# apollo1 register map
Vendor: Ambiq Micro; Series: Apollo; File version: 1.0
CPU: CM4 r1p0, little endian, MPU, FPU, 3 interrupt priority bits
Registers are 32-bit, read-write, reset 0x0 unless marked. A register's access mark holds for its fields unless they carry their own. Offsets are from the block's base; [hi:lo] are bit positions; 'fields as' and 'values as' point back to an identical list.

## IOMSTR0 — I2C/SPI Master
Base 0x50004000
Same registers: IOMSTR1 0x50005000
0x00 FIFO — FIFO Access Port
  [31:0] FIFO — FIFO access port.
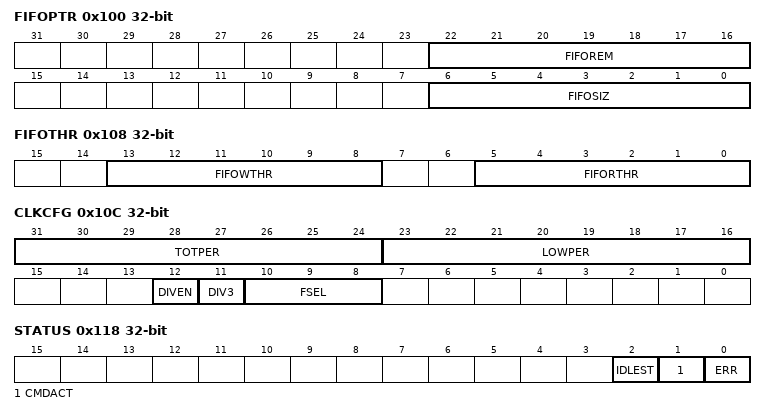
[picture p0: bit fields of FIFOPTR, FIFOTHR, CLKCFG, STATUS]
0x100 FIFOPTR — Current FIFO Pointers
  [22:16] FIFOREM — The number of bytes remaining in the FIFO (i.e. 64-FIFOSIZ).
  [6:0] FIFOSIZ — The number of bytes currently in the FIFO.
0x104 TLNGTH — Transfer Length
  [11:0] TLNGTH — Remaining transfer length.
0x108 FIFOTHR — FIFO Threshold Configuration
  [13:8] FIFOWTHR — FIFO write threshold.
  [5:0] FIFORTHR — FIFO read threshold.
0x10C CLKCFG — I/O Clock Configuration
  [31:24] TOTPER — Clock total count minus 1.
  [23:16] LOWPER — Clock low count minus 1.
  [12] DIVEN — Enable clock division by TOTPER.
    0=DIS (Disable TOTPER division. value.); 1=EN (Enable TOTPER division. value.)
  [11] DIV3 — Enable divide by 3.
    0=DIS (Select divide by 1. value.); 1=EN (Select divide by 3. value.)
  [10:8] FSEL — Select the input clock frequency.
    0=HFRC_DIV64 (Selects the HFRC / 64 as the input clock. value.); 1=HFRC (Selects the HFRC as the input clock. value.); 2=HFRC_DIV2 (Selects the HFRC / 2 as the input clock. value.); 3=HFRC_DIV4 (Selects the HFRC / 4 as the input clock. value.); 4=HFRC_DIV8 (Selects the HFRC / 8 as the input clock. value.); 5=HFRC_DIV16 (Selects the HFRC / 16 as the input clock. value.); 6=HFRC_DIV32 (Selects the HFRC / 32 as the input clock. value.)
0x110 CMD — Command Register
  [31:0] CMD — This register is the I/O Command.
    0=POS_LENGTH (LSB bit position of the CMD LENGTH field. value.); 8=POS_OFFSET (LSB bit position of the CMD OFFSET field. value.); 16=POS_ADDRESS (LSB bit position of the I2C CMD ADDRESS field. value.); 23=POS_UPLNGTH (LSB bit position of the SPI CMD UPLNGTH field. value.); 26=POS_10BIT (LSB bit position of the I2C CMD 10-bit field. value.); 27=POS_LSB (LSB bit position of the CMD LSB-first field. value.); 28=POS_CONT (LSB bit position of the CMD CONTinue field. value.); 29=POS_OPER (LSB bit position of the CMD OPERation field. value.); 255=MSK_LENGTH (LSB bit mask of the CMD LENGTH field. value.); 0xFF00=MSK_OFFSET (LSB bit mask of the CMD OFFSET field. value.); 0xFF0000=MSK_ADDRESS (LSB bit mask of the I2C CMD ADDRESS field. value.); 0x70000=MSK_CHNL (LSB bit mask of the SPI CMD CHANNEL field. value.); 0x7800000=MSK_UPLNGTH (LSB bit mask of the SPI CMD UPLNGTH field. value.); 0x4000000=MSK_10BIT (LSB bit mask of the I2C CMD 10-bit field. value.); 0x8000000=MSK_LSB (LSB bit mask of the CMD LSB-first field. value.); 0x10000000=MSK_CONT (LSB bit mask of the CMD CONTinue field. value.); 0xE0000000=MSK_OPER (LSB bit mask of the CMD OPERation field. value.)
0x114 CMDRPT — Command Repeat Register
  [4:0] CMDRPT — These bits hold the Command repeat count.
0x118 STATUS
  [2] IDLEST — This bit indicates if the I/O state machine is IDLE.
    1=IDLE (The I/O state machine is in the idle state. value.)
  [1] CMDACT — This bit indicates if the I/O Command is active.
    1=ACTIVE (An I/O command is active. value.)
  [0] ERR — This bit indicates if an error interrupt has occurred.
    1=ERROR (An error has been indicated by the IOM. value.)
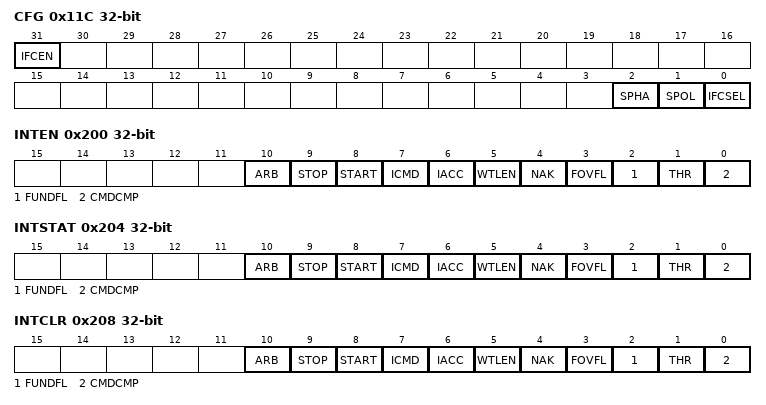
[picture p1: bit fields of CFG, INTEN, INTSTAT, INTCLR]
0x11C CFG — I/O Master Configuration
  [31] IFCEN — This bit enables the IO Master.
    0=DIS (Disable the IO Master. value.); 1=EN (Enable the IO Master. value.)
  [2] SPHA — This bit selects SPI phase.
    0=SAMPLE_LEADING_EDGE (Sample on the leading (first) clock edge. value.); 1=SAMPLE_TRAILING_EDGE (Sample on the trailing (second) clock edge. value.)
  [1] SPOL — This bit selects SPI polarity.
    0=CLK_BASE_0 (The base value of the clock is 0. value.); 1=CLK_BASE_1 (The base value of the clock is 1. value.)
  [0] IFCSEL — This bit selects the I/O interface.
    0=I2C (Selects I2C interface for the I/O Master. value.); 1=SPI (Selects SPI interface for the I/O Master. value.)
0x200 INTEN — IO Master Interrupts: Enable
  [10] ARB — This is the arbitration loss interrupt.
  [9] STOP — This is the STOP command interrupt.
  [8] START — This is the START command interrupt.
  [7] ICMD — This is the illegal command interrupt.
  [6] IACC — This is the illegal FIFO access interrupt.
  [5] WTLEN — This is the write length mismatch interrupt.
  [4] NAK — This is the I2C NAK interrupt.
  [3] FOVFL — This is the Read FIFO Overflow interrupt.
  [2] FUNDFL — This is the Write FIFO Underflow interrupt.
  [1] THR — This is the FIFO Threshold interrupt.
  [0] CMDCMP — This is the Command Complete interrupt.
0x204 INTSTAT — IO Master Interrupts: Status
  fields as INTEN
0x208 INTCLR — IO Master Interrupts: Clear
  fields as INTEN
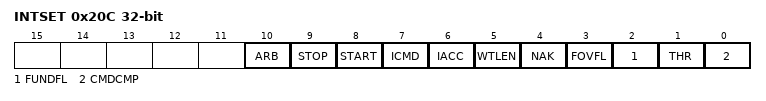
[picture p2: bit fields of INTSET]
0x20C INTSET — IO Master Interrupts: Set
  fields as INTEN

## Notices in the file
Copyright (C) 2012-2014 ARM Limited. All rights reserved.
Purpose: System Viewer Description (SVD) Example (Schema Version 1.1)
This is a description of a none-existent and incomplete device
for demonstration purposes only.
Redistribution and use in source and binary forms, with or without
modification, are permitted provided that the following conditions are met:
- Redistributions of source code must retain the above copyright
notice, this list of conditions and the following disclaimer.
- Redistributions in binary form must reproduce the above copyright
notice, this list of conditions and the following disclaimer in the
documentation and/or other materials provided with the distribution.
- Neither the name of ARM nor the names of its contributors may be used
to endorse or promote products derived from this software without
specific prior written permission.
THIS SOFTWARE IS PROVIDED BY THE COPYRIGHT HOLDERS AND CONTRIBUTORS "AS IS"
AND ANY EXPRESS OR IMPLIED WARRANTIES, INCLUDING, BUT NOT LIMITED TO, THE
IMPLIED WARRANTIES OF MERCHANTABILITY AND FITNESS FOR A PARTICULAR PURPOSE
ARE DISCLAIMED. IN NO EVENT SHALL COPYRIGHT HOLDERS AND CONTRIBUTORS BE
LIABLE FOR ANY DIRECT, INDIRECT, INCIDENTAL, SPECIAL, EXEMPLARY, OR
CONSEQUENTIAL DAMAGES (INCLUDING, BUT NOT LIMITED TO, PROCUREMENT OF
SUBSTITUTE GOODS OR SERVICES; LOSS OF USE, DATA, OR PROFITS; OR BUSINESS
INTERRUPTION) HOWEVER CAUSED AND ON ANY THEORY OF LIABILITY, WHETHER IN
CONTRACT, STRICT LIABILITY, OR TORT (INCLUDING NEGLIGENCE OR OTHERWISE)
ARISING IN ANY WAY OUT OF THE USE OF THIS SOFTWARE, EVEN IF ADVISED OF THE
POSSIBILITY OF SUCH DAMAGE.
